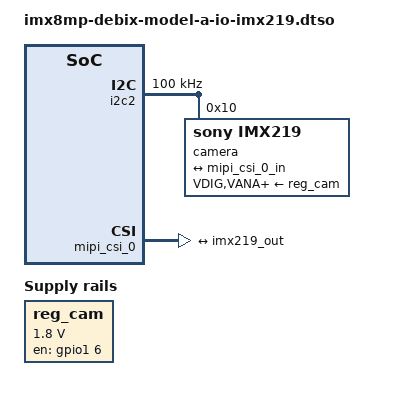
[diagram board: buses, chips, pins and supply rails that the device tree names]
// SPDX-License-Identifier: (GPL-2.0+ OR MIT)
/*
 * Copyright 2022 Ideas on Board Oy
 */

/dts-v1/;
/plugin/;

#include <dt-bindings/clock/imx8mp-clock.h>
#include <dt-bindings/gpio/gpio.h>
#include "imx8mp-pinfunc.h"

&{/} {
	/*
	 * The three camera regulators are controlled by a single GPIO. Declare
	 * a single regulator for the three supplies.
	 */
	reg_cam: regulator-cam {
		pinctrl-names = "default";
		pinctrl-0 = <&pinctrl_csi0_rst>;
		compatible = "regulator-fixed";
		regulator-name = "reg_cam";
		gpio = <&gpio1 6 GPIO_ACTIVE_HIGH>;
		enable-active-high;
		regulator-min-microvolt = <1800000>;
		regulator-max-microvolt = <1800000>;
	};
};

&i2c2 {
	clock-frequency = <100000>;
	status = "okay";

	camera@10 {
		compatible = "sony,imx219";
		reg = <0x10>;

		clocks = <&clk IMX8MP_CLK_IPP_DO_CLKO2>;
		clock-names = "xclk";
		assigned-clocks = <&clk IMX8MP_CLK_IPP_DO_CLKO2>;
		assigned-clock-parents = <&clk IMX8MP_CLK_24M>;
		assigned-clock-rates = <24000000>;

		VDIG-supply = <&reg_cam>;
		VANA-supply = <&reg_cam>;
		VDDL-supply = <&reg_cam>;

		rotation = <0>;
		orientation = <2>; /* External camera */

		port {
			imx219_out: endpoint {
				remote-endpoint = <&mipi_csi_0_in>;
				data-lanes = <1 2>;
				clock-noncontinuous;
				link-frequencies = /bits/ 64 <456000000>;
			};
		};
	};
};

&iomuxc {
	pinctrl_csi0_rst: csi0_rst_grp {
		fsl,pins = <
			MX8MP_IOMUXC_GPIO1_IO06__GPIO1_IO06	0x19
		>;
	};
};

&mipi_csi_0 {
	status = "okay";

	ports {
		port@0 {
			mipi_csi_0_in: endpoint {
				remote-endpoint = <&imx219_out>;
				clock-lanes = <0>;
				data-lanes = <1 2>;
			};
		};
	};
};
